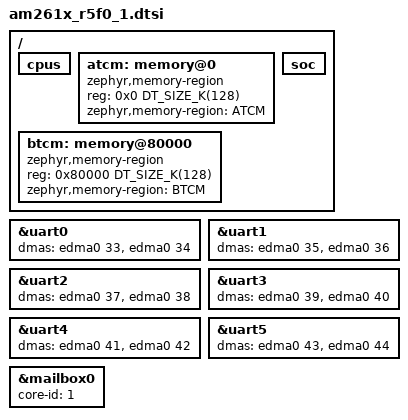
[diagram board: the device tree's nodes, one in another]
/*
 * Copyright (c) 2025 Texas Instruments Incorporated
 *
 * SPDX-License-Identifier: Apache-2.0
 */

#include "am261x.dtsi"

/ {

	cpus {
		/delete-node/ cpu0;
	};

	atcm: memory@0 {
		device_type = "memory";
		compatible = "zephyr,memory-region";
		reg = <0x0 DT_SIZE_K(128)>;
		zephyr,memory-region = "ATCM";
	};

	btcm: memory@80000 {
		device_type = "memory";
		compatible = "zephyr,memory-region";
		reg = <0x80000 DT_SIZE_K(128)>;
		zephyr,memory-region = "BTCM";
	};

    soc {
        /delete-node/ gpio0;
    };
};

&uart0 {
	dmas = <&edma0 33>, <&edma0 34>;
	dma-names = "tx", "rx";
};

&uart1 {
	dmas = <&edma0 35>, <&edma0 36>;
	dma-names = "tx", "rx";
};

&uart2 {
	dmas = <&edma0 37>, <&edma0 38>;
	dma-names = "tx", "rx";
};

&uart3 {
	dmas = <&edma0 39>, <&edma0 40>;
	dma-names = "tx", "rx";
};

&uart4 {
	dmas = <&edma0 41>, <&edma0 42>;
	dma-names = "tx", "rx";
};

&uart5 {
	dmas = <&edma0 43>, <&edma0 44>;
	dma-names = "tx", "rx";
};

&mailbox0 {
	core-id = <1>;
};


